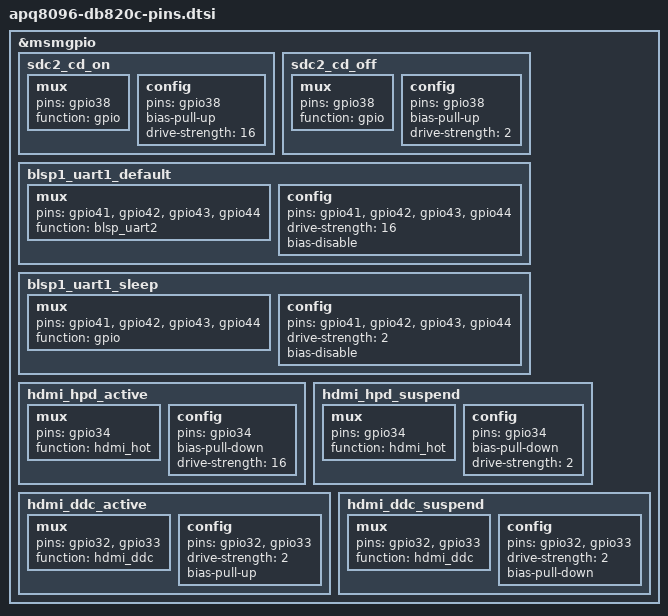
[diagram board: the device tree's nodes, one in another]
// SPDX-License-Identifier: GPL-2.0-only
/*
 * Copyright (c) 2013-2016, The Linux Foundation. All rights reserved.
 */
&msmgpio {
	sdc2_cd_on: sdc2_cd_on {
		mux {
			pins = "gpio38";
			function = "gpio";
		};

		config {
			pins = "gpio38";
			bias-pull-up;		/* pull up */
			drive-strength = <16>;	/* 16 MA */
		};
	};

	sdc2_cd_off: sdc2_cd_off {
		mux {
			pins = "gpio38";
			function = "gpio";
		};

		config {
			pins = "gpio38";
			bias-pull-up;		/* pull up */
			drive-strength = <2>;	/* 2 MA */
		};
	};

	blsp1_uart1_default: blsp1_uart1_default {
		mux {
			pins = "gpio41", "gpio42", "gpio43", "gpio44";
			function = "blsp_uart2";
		};

		config {
			pins = "gpio41", "gpio42", "gpio43", "gpio44";
			drive-strength = <16>;
			bias-disable;
		};
	};

	blsp1_uart1_sleep: blsp1_uart1_sleep {
		mux {
			pins = "gpio41", "gpio42", "gpio43", "gpio44";
			function = "gpio";
		};

		config {
			pins = "gpio41", "gpio42", "gpio43", "gpio44";
			drive-strength = <2>;
			bias-disable;
		};
	};

	hdmi_hpd_active: hdmi_hpd_active {
		mux {
			pins = "gpio34";
			function = "hdmi_hot";
		};

		config {
			pins = "gpio34";
			bias-pull-down;
			drive-strength = <16>;
		};
	};

	hdmi_hpd_suspend: hdmi_hpd_suspend {
		mux {
			pins = "gpio34";
			function = "hdmi_hot";
		};

		config {
			pins = "gpio34";
			bias-pull-down;
			drive-strength = <2>;
		};
	};

	hdmi_ddc_active: hdmi_ddc_active {
		mux {
			pins = "gpio32", "gpio33";
			function = "hdmi_ddc";
		};

		config {
			pins = "gpio32", "gpio33";
			drive-strength = <2>;
			bias-pull-up;
		};
	};

	hdmi_ddc_suspend: hdmi_ddc_suspend {
		mux {
			pins = "gpio32", "gpio33";
			function = "hdmi_ddc";
		};

		config {
			pins = "gpio32", "gpio33";
			drive-strength = <2>;
			bias-pull-down;
		};
	};
};
